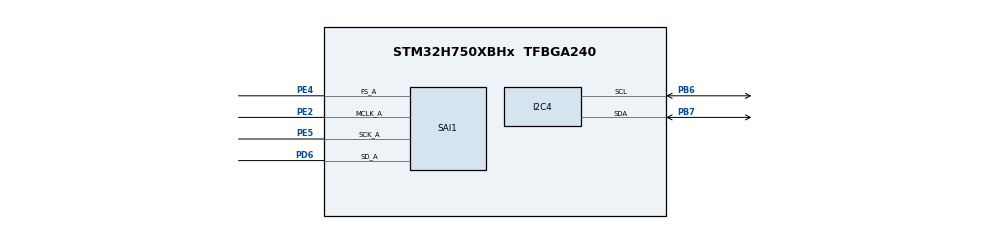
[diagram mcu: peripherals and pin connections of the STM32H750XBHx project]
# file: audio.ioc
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CORTEX_M7.default_mode_Activation=1
Mcu.Family=STM32H7
Mcu.Name=STM32H750XBHx
Mcu.Package=TFBGA240
NVIC.I2C4_ER_IRQn=true\:0\:0\:false\:false\:true\:true\:true\:true
NVIC.I2C4_EV_IRQn=true\:0\:0\:false\:false\:true\:true\:true\:true
NVIC.PriorityGroup=NVIC_PRIORITYGROUP_4
PB6.Mode=I2C
PB6.Signal=I2C4_SCL
PB7.Mode=I2C
PB7.Signal=I2C4_SDA
PD6.Mode=SAI_A_MasterWithClock
PD6.Signal=SAI1_SD_A
PE2.Mode=SAI_A_MasterWithClock
PE2.Signal=SAI1_MCLK_A
PE4.Mode=SAI_A_MasterWithClock
PE4.Signal=SAI1_FS_A
PE5.Mode=SAI_A_MasterWithClock
PE5.Signal=SAI1_SCK_A
ProjectManager.HeapSize=0x200
ProjectManager.StackSize=0x400
ProjectManager.TargetToolchain=STM32CubeIDE
RCC.ADCFreq_Value=129000000
RCC.APB1Freq_Value=64000000
RCC.APB2Freq_Value=64000000
RCC.APB3Freq_Value=64000000
RCC.APB4Freq_Value=64000000
RCC.CortexFreq_Value=64000000
RCC.HCLKFreq_Value=64000000
RCC.SYSCLKFreq_VALUE=64000000
RCC.USBFreq_Value=129000000
SAI1.ErrorAudioFreq-SAI_A_MasterWithClock=162.45 %
SAI1.InitProtocol-SAI_A_MasterWithClock=Enable
SAI1.Instance-SAI_A_MasterWithClock=SAI$Index_Block_A
SAI1.MClockEnable-SAI_A_MasterWithClock=SAI_MASTERCLOCK_ENABLE
SAI1.RealAudioFreq-SAI_A_MasterWithClock=503.906 KHz
SAI1.VirtualMode-SAI_A_MasterWithClock=VM_MASTER
SAI1.VirtualProtocol-SAI_A_BASIC=VM_BASIC_PROTOCOL
VP_CRC_VS_CRC.Mode=CRC_Activate
VP_MEMORYMAP_VS_MEMORYMAP.Mode=CurAppReg
VP_PDM2PCM_VS_PDM2PCM.Mode=PDM2PCM_Channel
VP_SAI1_VP_$IpInstance_SAIA_SAI_BASIC.Mode=SAI_A_BASIC
board=custom

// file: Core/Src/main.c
/* USER CODE BEGIN Header */
/**
  ******************************************************************************
  * @file           : main.c
  * @brief          : Main program body
  ******************************************************************************
  * @attention
  *
  * Copyright (c) 2026 STMicroelectronics.
  * All rights reserved.
  *
  * This software is licensed under terms that can be found in the LICENSE file
  * in the root directory of this software component.
  * If no LICENSE file comes with this software, it is provided AS-IS.
  *
  ******************************************************************************
  */
/* USER CODE END Header */
#include "main.h"
#include "pdm2pcm.h"

/* USER CODE BEGIN Includes */
#include "stm32h750b_discovery_audio.h"
/* USER CODE END Includes */

CRC_HandleTypeDef hcrc;

I2C_HandleTypeDef hi2c4;

SAI_HandleTypeDef hsai_BlockA1;

void SystemClock_Config(void);
static void MPU_Config(void);
static void MX_GPIO_Init(void);
static void MX_I2C4_Init(void);
static void MX_SAI1_Init(void);
static void MX_CRC_Init(void);

int main(void)
{

  /* MPU Configuration--------------------------------------------------------*/
  MPU_Config();

  /* MCU Configuration--------------------------------------------------------*/

  /* Reset of all peripherals, Initializes the Flash interface and the Systick. */
  HAL_Init();

  /* Configure the system clock */
  SystemClock_Config();

  /* Initialize all configured peripherals */
  MX_GPIO_Init();
  MX_I2C4_Init();
  MX_SAI1_Init();
  MX_CRC_Init();
  MX_PDM2PCM_Init();

  /* Infinite loop */
  while (1)
  {

  }
}

void SystemClock_Config(void)
{
  RCC_OscInitTypeDef RCC_OscInitStruct = {0};
  RCC_ClkInitTypeDef RCC_ClkInitStruct = {0};

  /** Supply configuration update enable
  */
  HAL_PWREx_ConfigSupply(PWR_LDO_SUPPLY);

  /** Configure the main internal regulator output voltage
  */
  __HAL_PWR_VOLTAGESCALING_CONFIG(PWR_REGULATOR_VOLTAGE_SCALE3);

  while(!__HAL_PWR_GET_FLAG(PWR_FLAG_VOSRDY)) {}

  /** Initializes the RCC Oscillators according to the specified parameters
  * in the RCC_OscInitTypeDef structure.
  */
  RCC_OscInitStruct.OscillatorType = RCC_OSCILLATORTYPE_HSI;
  RCC_OscInitStruct.HSIState = RCC_HSI_DIV1;
  RCC_OscInitStruct.HSICalibrationValue = RCC_HSICALIBRATION_DEFAULT;
  RCC_OscInitStruct.PLL.PLLState = RCC_PLL_ON;
  RCC_OscInitStruct.PLL.PLLSource = RCC_PLLSOURCE_HSI;
  RCC_OscInitStruct.PLL.PLLM = 32;
  RCC_OscInitStruct.PLL.PLLN = 129;
  RCC_OscInitStruct.PLL.PLLP = 2;
  RCC_OscInitStruct.PLL.PLLQ = 2;
  RCC_OscInitStruct.PLL.PLLR = 2;
  RCC_OscInitStruct.PLL.PLLRGE = RCC_PLL1VCIRANGE_1;
  RCC_OscInitStruct.PLL.PLLVCOSEL = RCC_PLL1VCOWIDE;
  RCC_OscInitStruct.PLL.PLLFRACN = 0;
  if (HAL_RCC_OscConfig(&RCC_OscInitStruct) != HAL_OK)
  {
    Error_Handler();
  }

  /** Initializes the CPU, AHB and APB buses clocks
  */
  RCC_ClkInitStruct.ClockType = RCC_CLOCKTYPE_HCLK|RCC_CLOCKTYPE_SYSCLK
                              |RCC_CLOCKTYPE_PCLK1|RCC_CLOCKTYPE_PCLK2
                              |RCC_CLOCKTYPE_D3PCLK1|RCC_CLOCKTYPE_D1PCLK1;
  RCC_ClkInitStruct.SYSCLKSource = RCC_SYSCLKSOURCE_HSI;
  RCC_ClkInitStruct.SYSCLKDivider = RCC_SYSCLK_DIV1;
  RCC_ClkInitStruct.AHBCLKDivider = RCC_HCLK_DIV1;
  RCC_ClkInitStruct.APB3CLKDivider = RCC_APB3_DIV1;
  RCC_ClkInitStruct.APB1CLKDivider = RCC_APB1_DIV1;
  RCC_ClkInitStruct.APB2CLKDivider = RCC_APB2_DIV1;
  RCC_ClkInitStruct.APB4CLKDivider = RCC_APB4_DIV1;

  if (HAL_RCC_ClockConfig(&RCC_ClkInitStruct, FLASH_LATENCY_1) != HAL_OK)
  {
    Error_Handler();
  }
}

static void MX_CRC_Init(void)
{

  hcrc.Instance = CRC;
  hcrc.Init.DefaultPolynomialUse = DEFAULT_POLYNOMIAL_ENABLE;
  hcrc.Init.DefaultInitValueUse = DEFAULT_INIT_VALUE_ENABLE;
  hcrc.Init.InputDataInversionMode = CRC_INPUTDATA_INVERSION_NONE;
  hcrc.Init.OutputDataInversionMode = CRC_OUTPUTDATA_INVERSION_DISABLE;
  hcrc.InputDataFormat = CRC_INPUTDATA_FORMAT_BYTES;
  if (HAL_CRC_Init(&hcrc) != HAL_OK)
  {
    Error_Handler();
  }
  __HAL_CRC_DR_RESET(&hcrc);

}

static void MX_I2C4_Init(void)
{

  hi2c4.Instance = I2C4;
  hi2c4.Init.Timing = 0x10707DBC;
  hi2c4.Init.OwnAddress1 = 0;
  hi2c4.Init.AddressingMode = I2C_ADDRESSINGMODE_7BIT;
  hi2c4.Init.DualAddressMode = I2C_DUALADDRESS_DISABLE;
  hi2c4.Init.OwnAddress2 = 0;
  hi2c4.Init.OwnAddress2Masks = I2C_OA2_NOMASK;
  hi2c4.Init.GeneralCallMode = I2C_GENERALCALL_DISABLE;
  hi2c4.Init.NoStretchMode = I2C_NOSTRETCH_DISABLE;
  if (HAL_I2C_Init(&hi2c4) != HAL_OK)
  {
    Error_Handler();
  }

  /** Configure Analogue filter
  */
  if (HAL_I2CEx_ConfigAnalogFilter(&hi2c4, I2C_ANALOGFILTER_ENABLE) != HAL_OK)
  {
    Error_Handler();
  }

  /** Configure Digital filter
  */
  if (HAL_I2CEx_ConfigDigitalFilter(&hi2c4, 0) != HAL_OK)
  {
    Error_Handler();
  }

}

static void MX_SAI1_Init(void)
{

  hsai_BlockA1.Instance = SAI1_Block_A;
  hsai_BlockA1.Init.AudioMode = SAI_MODEMASTER_TX;
  hsai_BlockA1.Init.Synchro = SAI_ASYNCHRONOUS;
  hsai_BlockA1.Init.OutputDrive = SAI_OUTPUTDRIVE_DISABLE;
  hsai_BlockA1.Init.NoDivider = SAI_MCK_OVERSAMPLING_DISABLE;
  hsai_BlockA1.Init.MckOverSampling = SAI_MCK_OVERSAMPLING_DISABLE;
  hsai_BlockA1.Init.FIFOThreshold = SAI_FIFOTHRESHOLD_EMPTY;
  hsai_BlockA1.Init.AudioFrequency = SAI_AUDIO_FREQUENCY_192K;
  hsai_BlockA1.Init.SynchroExt = SAI_SYNCEXT_DISABLE;
  hsai_BlockA1.Init.MonoStereoMode = SAI_STEREOMODE;
  hsai_BlockA1.Init.CompandingMode = SAI_NOCOMPANDING;
  hsai_BlockA1.Init.TriState = SAI_OUTPUT_NOTRELEASED;
  if (HAL_SAI_InitProtocol(&hsai_BlockA1, SAI_I2S_STANDARD, SAI_PROTOCOL_DATASIZE_16BIT, 2) != HAL_OK)
  {
    Error_Handler();
  }

}

static void MX_GPIO_Init(void)
{

  /* GPIO Ports Clock Enable */
  __HAL_RCC_GPIOB_CLK_ENABLE();
  __HAL_RCC_GPIOD_CLK_ENABLE();
  __HAL_RCC_GPIOE_CLK_ENABLE();

}

 /* MPU Configuration */

void MPU_Config(void)
{
  MPU_Region_InitTypeDef MPU_InitStruct = {0};

  /* Disables the MPU */
  HAL_MPU_Disable();

  /** Initializes and configures the Region and the memory to be protected
  */
  MPU_InitStruct.Enable = MPU_REGION_ENABLE;
  MPU_InitStruct.Number = MPU_REGION_NUMBER0;
  MPU_InitStruct.BaseAddress = 0x0;
  MPU_InitStruct.Size = MPU_REGION_SIZE_4GB;
  MPU_InitStruct.SubRegionDisable = 0x87;
  MPU_InitStruct.TypeExtField = MPU_TEX_LEVEL0;
  MPU_InitStruct.AccessPermission = MPU_REGION_NO_ACCESS;
  MPU_InitStruct.DisableExec = MPU_INSTRUCTION_ACCESS_DISABLE;
  MPU_InitStruct.IsShareable = MPU_ACCESS_SHAREABLE;
  MPU_InitStruct.IsCacheable = MPU_ACCESS_NOT_CACHEABLE;
  MPU_InitStruct.IsBufferable = MPU_ACCESS_NOT_BUFFERABLE;

  HAL_MPU_ConfigRegion(&MPU_InitStruct);
  /* Enables the MPU */
  HAL_MPU_Enable(MPU_PRIVILEGED_DEFAULT);

}

void Error_Handler(void)
{
  __disable_irq();
  while (1)
  {
  }
}
